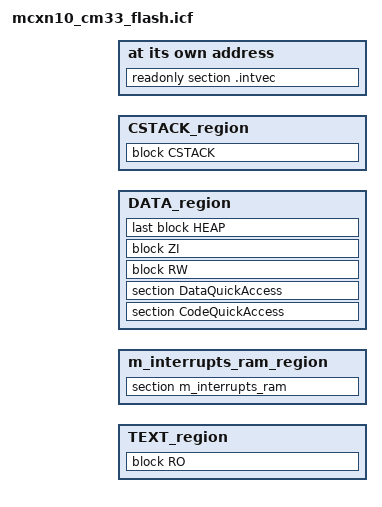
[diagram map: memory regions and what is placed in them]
/*
** ###################################################################
**     Processors:         
**
**     Compiler:            IAR ANSI C/C++ Compiler for ARM
**     Reference manual:    
**     Version:             rev. 5.0, 2021-07-28
**     Build:               b210730
**
**     Abstract:
**         Linker file for the IAR ANSI C/C++ Compiler for ARM
**
**     Copyright 2016 Freescale Semiconductor, Inc.
**     Copyright 2016-2022 NXP
**     All rights reserved.
**
**     SPDX-License-Identifier: BSD-3-Clause
**
**     http:                 www.nxp.com
**     mail:                 support@nxp.com
**
** ###################################################################
*/

/* USB BDT size */
define symbol usb_bdt_size             = 0x0;
/* Stack and Heap Sizes */
if (isdefinedsymbol(__stack_size__)) {
  define symbol __size_cstack__        = __stack_size__;
} else {
  define symbol __size_cstack__        = 0x1000;
}

if (isdefinedsymbol(__heap_size__)) {
  define symbol __size_heap__          = __heap_size__;
} else {
  define symbol __size_heap__          = 0x0400;
}

define symbol __ram_vector_table_size__        =  isdefinedsymbol(__ram_vector_table__) ? 0x00000180 : 0;
define symbol __ram_vector_table_offset__      =  isdefinedsymbol(__ram_vector_table__) ? 0x0000017F : 0;

/*
  Flash partition layout selector - this single linker file covers both
  supported layouts. The custom one is selected by the __mcuboot_main_flash_only__
  linker symbol, which is defined by the mcuboot middleware when the Kconfig
  option MCUX_COMPONENT_middleware.mcuboot.mcxn_custom_cfg.main_flash_only
  is enabled. See flash_partitioning.h of the mcuboot_opensource example.

  Default configuration (__mcuboot_main_flash_only__ not defined)
  Bootloader located in Bank 1 IFR 0 Region (0x0100_8000 - 0x0100_FFFF)
  This configuration supports flash remap

  0x0000_0000  +------------------------+ Flash Start
               | Application_Primary    | 1024 kB
  0x0010_0000  +------------------------+
               | Application_Secondary  | 1024 kB
  0x0020_0000  +------------------------+
                          ...
  0x0100_8000  +------------------------+
               | Bootloader             | 32 kB   <- this image
  0x0100_FFFF  +------------------------+

  RAM: 0x2000_0000 - 0x2004_FFFF (320 kB)

  Custom configuration (__mcuboot_main_flash_only__ defined)
  Bootloader located in main flash
  This configuration supports mbedTLS by default and optionally encrypted XIP using NPX

  0x0000_0000  +------------------------+ Flash Start
               | Bootloader             | 256 kB  <- this image
  0x0004_0000  +------------------------+
               | Application_Primary    | 896 kB
  0x0012_0000  +------------------------+
               | Application_Secondary  | 896 kB
  0x0020_0000  +------------------------+

  RAM: 0x3000_0000 - 0x3004_FFFF (320 kB)

  Note: the custom configuration addresses the flash and RAM through their
  secure aliases (0x1000_0000 / 0x3000_0000), the default one through the
  non-secure aliases (0x0000_0000 / 0x2000_0000).
*/

define symbol m_interrupts_start               = isdefinedsymbol(__mcuboot_main_flash_only__) ? 0x10000000 : 0x01008000;
define symbol m_interrupts_end                 = isdefinedsymbol(__mcuboot_main_flash_only__) ? 0x100003FF : 0x010083FF;

define symbol m_text_start                     = isdefinedsymbol(__mcuboot_main_flash_only__) ? 0x10000400 : 0x01008400;
define symbol m_text_end                       = isdefinedsymbol(__mcuboot_main_flash_only__) ? 0x1003FFFF : 0x0100FFFF;

define symbol m_interrupts_ram_base            = isdefinedsymbol(__mcuboot_main_flash_only__) ? 0x30000000 : 0x20000000;

define symbol m_interrupts_ram_start           = m_interrupts_ram_base;
define symbol m_interrupts_ram_end             = m_interrupts_ram_base + __ram_vector_table_offset__;

define symbol m_data_start                     = m_interrupts_ram_start + __ram_vector_table_size__;
define symbol m_data_end                       = m_interrupts_ram_base + 0x0004FFFF;

/*
define symbol m_usb_sram_start                 = 0x400BA000;
define symbol m_usb_sram_end                   = 0x400BAFFF;
*/

define exported symbol __VECTOR_TABLE          = m_interrupts_start;
define exported symbol __VECTOR_RAM            = isdefinedsymbol(__ram_vector_table__) ? m_interrupts_ram_start : m_interrupts_start;
define exported symbol __RAM_VECTOR_TABLE_SIZE = __ram_vector_table_size__;

define memory mem with size = 4G;

define region TEXT_region             = mem:[from m_interrupts_start to m_interrupts_end]
                                      | mem:[from m_text_start to m_text_end];
define region m_interrupts_ram_region = mem:[from m_interrupts_ram_start to m_interrupts_ram_end];
define region DATA_region             = mem:[from m_data_start to m_data_end - __size_cstack__];
define region CSTACK_region           = mem:[from m_data_end-__size_cstack__ + 1 to m_data_end];

define block CSTACK    with alignment = 8, size = __size_cstack__   { };
define block HEAP      with alignment = 8, size = __size_heap__     { };
define block RO        { readonly };
define block RW        { readwrite };
define block ZI        { zi };

/* regions for USB */
/*
define region USB_BDT_region = mem:[from m_usb_sram_start to m_usb_sram_start + usb_bdt_size - 1];
define region USB_SRAM_region = mem:[from m_usb_sram_start + usb_bdt_size to m_usb_sram_end];
*/

initialize by copy { readwrite, section .textrw, section CodeQuickAccess, section DataQuickAccess};

initialize by copy {
  object mflash_drv.o
};

/*
do not initialize  { section .noinit, section m_usb_bdt, section m_usb_global  };
*/
do not initialize  { section .noinit };

place at address mem: m_interrupts_start    { readonly section .intvec };
place in TEXT_region                        { block RO };
place in m_interrupts_ram_region            { section m_interrupts_ram };
place in DATA_region                        { section CodeQuickAccess, section DataQuickAccess };
place in DATA_region                        { block RW };
place in DATA_region                        { block ZI };
place in DATA_region                        { last block HEAP };
place in CSTACK_region                      { block CSTACK };
/*
place in USB_BDT_region                     { section m_usb_bdt };
place in USB_SRAM_region                    { section m_usb_global };
*/
